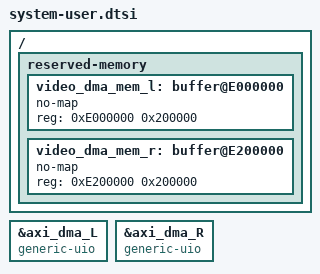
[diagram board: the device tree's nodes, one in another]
/include/ "system-conf.dtsi"

/ {
    reserved-memory {
        #address-cells = <1>;
        #size-cells = <1>;
        ranges;

        video_dma_mem_l: buffer@E000000 {
            no-map;
            reg = <0xE000000 0x200000>;   /* 2MB for left camera */
        };
        
        video_dma_mem_r: buffer@E200000 {
            no-map;
            reg = <0xE200000 0x200000>;   /* 2MB for right camera */
        };
    };
};

&axi_dma_L {
    compatible = "generic-uio";
};

&axi_dma_R {
    compatible = "generic-uio";
};
